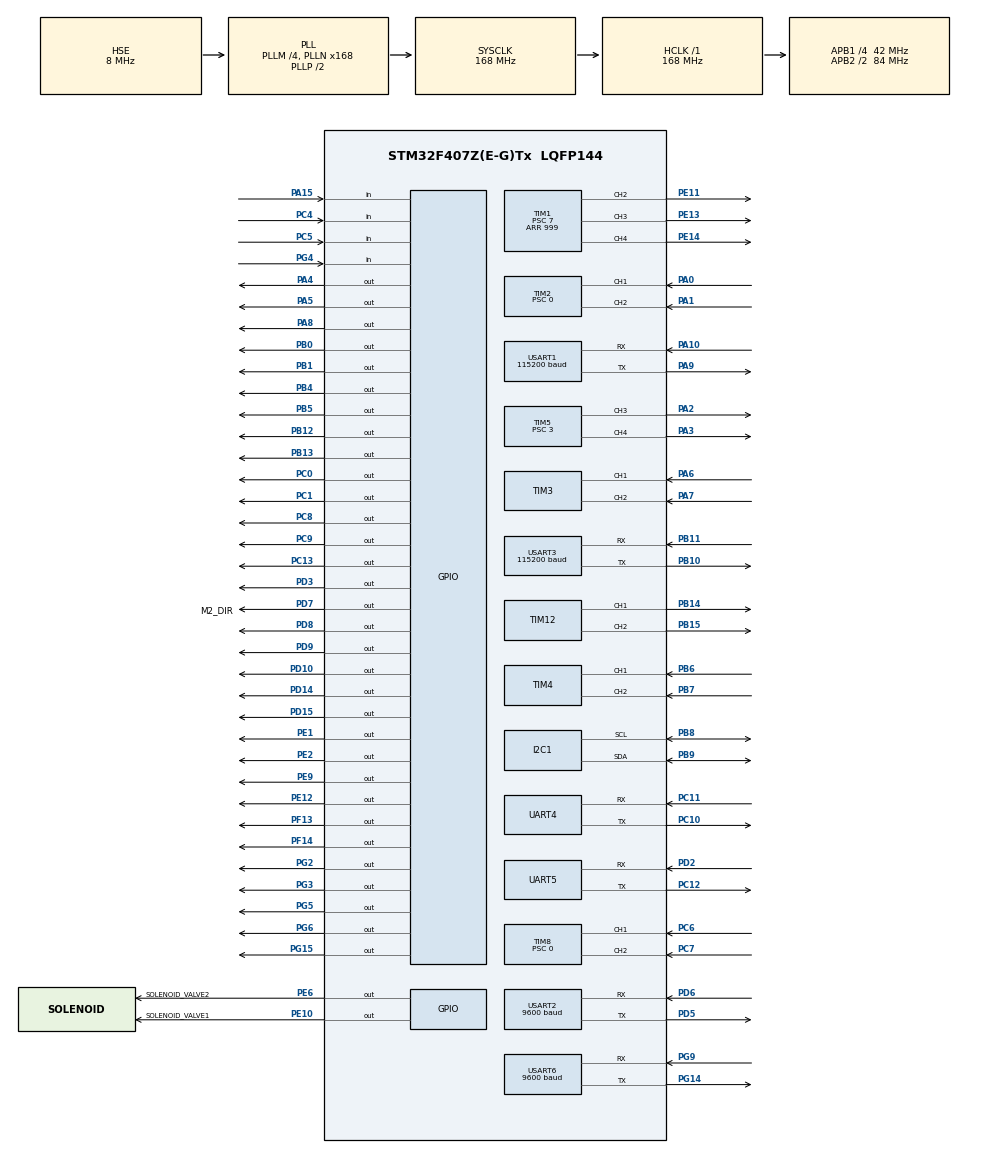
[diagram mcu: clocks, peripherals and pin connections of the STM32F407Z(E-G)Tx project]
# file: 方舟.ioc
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Dma.Request0=UART4_RX
Dma.Request1=UART4_TX
Dma.Request2=USART1_RX
Dma.Request3=USART1_TX
Dma.Request4=USART2_RX
Dma.Request5=USART2_TX
Dma.Request6=UART5_RX
Dma.Request7=UART5_TX
Dma.Request8=USART6_RX
Dma.Request9=USART6_TX
Dma.UART4_RX.0.Direction=DMA_PERIPH_TO_MEMORY
Dma.UART4_RX.0.FIFOMode=DMA_FIFOMODE_DISABLE
Dma.UART4_RX.0.Instance=DMA1_Stream2
Dma.UART4_RX.0.MemDataAlignment=DMA_MDATAALIGN_BYTE
Dma.UART4_RX.0.MemInc=DMA_MINC_ENABLE
Dma.UART4_RX.0.Mode=DMA_CIRCULAR
Dma.UART4_RX.0.PeriphDataAlignment=DMA_PDATAALIGN_BYTE
Dma.UART4_RX.0.PeriphInc=DMA_PINC_DISABLE
Dma.UART4_RX.0.Priority=DMA_PRIORITY_LOW
Dma.UART4_TX.1.Direction=DMA_MEMORY_TO_PERIPH
Dma.UART4_TX.1.FIFOMode=DMA_FIFOMODE_DISABLE
Dma.UART4_TX.1.Instance=DMA1_Stream4
Dma.UART4_TX.1.MemDataAlignment=DMA_MDATAALIGN_BYTE
Dma.UART4_TX.1.MemInc=DMA_MINC_ENABLE
Dma.UART4_TX.1.Mode=DMA_NORMAL
Dma.UART4_TX.1.PeriphDataAlignment=DMA_PDATAALIGN_BYTE
Dma.UART4_TX.1.PeriphInc=DMA_PINC_DISABLE
Dma.UART4_TX.1.Priority=DMA_PRIORITY_LOW
Dma.UART5_RX.6.Direction=DMA_PERIPH_TO_MEMORY
Dma.UART5_RX.6.FIFOMode=DMA_FIFOMODE_DISABLE
Dma.UART5_RX.6.Instance=DMA1_Stream0
Dma.UART5_RX.6.MemDataAlignment=DMA_MDATAALIGN_BYTE
Dma.UART5_RX.6.MemInc=DMA_MINC_ENABLE
Dma.UART5_RX.6.Mode=DMA_CIRCULAR
Dma.UART5_RX.6.PeriphDataAlignment=DMA_PDATAALIGN_BYTE
Dma.UART5_RX.6.PeriphInc=DMA_PINC_DISABLE
Dma.UART5_RX.6.Priority=DMA_PRIORITY_LOW
Dma.UART5_TX.7.Direction=DMA_MEMORY_TO_PERIPH
Dma.UART5_TX.7.FIFOMode=DMA_FIFOMODE_DISABLE
Dma.UART5_TX.7.Instance=DMA1_Stream7
Dma.UART5_TX.7.MemDataAlignment=DMA_MDATAALIGN_BYTE
Dma.UART5_TX.7.MemInc=DMA_MINC_ENABLE
Dma.UART5_TX.7.Mode=DMA_NORMAL
Dma.UART5_TX.7.PeriphDataAlignment=DMA_PDATAALIGN_BYTE
Dma.UART5_TX.7.PeriphInc=DMA_PINC_DISABLE
Dma.UART5_TX.7.Priority=DMA_PRIORITY_LOW
Dma.USART1_RX.2.Direction=DMA_PERIPH_TO_MEMORY
Dma.USART1_RX.2.FIFOMode=DMA_FIFOMODE_DISABLE
Dma.USART1_RX.2.Instance=DMA2_Stream2
Dma.USART1_RX.2.MemDataAlignment=DMA_MDATAALIGN_BYTE
Dma.USART1_RX.2.MemInc=DMA_MINC_ENABLE
Dma.USART1_RX.2.Mode=DMA_CIRCULAR
Dma.USART1_RX.2.PeriphDataAlignment=DMA_PDATAALIGN_BYTE
Dma.USART1_RX.2.PeriphInc=DMA_PINC_DISABLE
Dma.USART1_RX.2.Priority=DMA_PRIORITY_LOW
Dma.USART1_TX.3.Direction=DMA_MEMORY_TO_PERIPH
Dma.USART1_TX.3.FIFOMode=DMA_FIFOMODE_DISABLE
Dma.USART1_TX.3.Instance=DMA2_Stream7
Dma.USART1_TX.3.MemDataAlignment=DMA_MDATAALIGN_BYTE
Dma.USART1_TX.3.MemInc=DMA_MINC_ENABLE
Dma.USART1_TX.3.Mode=DMA_NORMAL
Dma.USART1_TX.3.PeriphDataAlignment=DMA_PDATAALIGN_BYTE
Dma.USART1_TX.3.PeriphInc=DMA_PINC_DISABLE
Dma.USART1_TX.3.Priority=DMA_PRIORITY_LOW
Dma.USART2_RX.4.Direction=DMA_PERIPH_TO_MEMORY
Dma.USART2_RX.4.FIFOMode=DMA_FIFOMODE_DISABLE
Dma.USART2_RX.4.Instance=DMA1_Stream5
Dma.USART2_RX.4.MemDataAlignment=DMA_MDATAALIGN_BYTE
Dma.USART2_RX.4.MemInc=DMA_MINC_ENABLE
Dma.USART2_RX.4.Mode=DMA_CIRCULAR
Dma.USART2_RX.4.PeriphDataAlignment=DMA_PDATAALIGN_BYTE
Dma.USART2_RX.4.PeriphInc=DMA_PINC_DISABLE
Dma.USART2_RX.4.Priority=DMA_PRIORITY_LOW
Dma.USART2_TX.5.Direction=DMA_MEMORY_TO_PERIPH
Dma.USART2_TX.5.FIFOMode=DMA_FIFOMODE_DISABLE
Dma.USART2_TX.5.Instance=DMA1_Stream6
Dma.USART2_TX.5.MemDataAlignment=DMA_MDATAALIGN_BYTE
Dma.USART2_TX.5.MemInc=DMA_MINC_ENABLE
Dma.USART2_TX.5.Mode=DMA_NORMAL
Dma.USART2_TX.5.PeriphDataAlignment=DMA_PDATAALIGN_BYTE
Dma.USART2_TX.5.PeriphInc=DMA_PINC_DISABLE
Dma.USART2_TX.5.Priority=DMA_PRIORITY_LOW
Dma.USART6_RX.8.Direction=DMA_PERIPH_TO_MEMORY
Dma.USART6_RX.8.FIFOMode=DMA_FIFOMODE_DISABLE
Dma.USART6_RX.8.Instance=DMA2_Stream1
Dma.USART6_RX.8.MemDataAlignment=DMA_MDATAALIGN_BYTE
Dma.USART6_RX.8.MemInc=DMA_MINC_ENABLE
Dma.USART6_RX.8.Mode=DMA_CIRCULAR
Dma.USART6_RX.8.PeriphDataAlignment=DMA_PDATAALIGN_BYTE
Dma.USART6_RX.8.PeriphInc=DMA_PINC_DISABLE
Dma.USART6_RX.8.Priority=DMA_PRIORITY_LOW
Dma.USART6_TX.9.Direction=DMA_MEMORY_TO_PERIPH
Dma.USART6_TX.9.FIFOMode=DMA_FIFOMODE_DISABLE
Dma.USART6_TX.9.Instance=DMA2_Stream6
Dma.USART6_TX.9.MemDataAlignment=DMA_MDATAALIGN_BYTE
Dma.USART6_TX.9.MemInc=DMA_MINC_ENABLE
Dma.USART6_TX.9.Mode=DMA_NORMAL
Dma.USART6_TX.9.PeriphDataAlignment=DMA_PDATAALIGN_BYTE
Dma.USART6_TX.9.PeriphInc=DMA_PINC_DISABLE
Dma.USART6_TX.9.Priority=DMA_PRIORITY_LOW
I2C1.I2C_Mode=I2C_Fast
Mcu.Family=STM32F4
Mcu.Name=STM32F407Z(E-G)Tx
Mcu.Package=LQFP144
NVIC.DMA1_Stream0_IRQn=true\:0\:0\:false\:false\:true\:false\:true\:true
NVIC.DMA1_Stream2_IRQn=true\:0\:0\:false\:false\:true\:false\:true\:true
NVIC.DMA1_Stream4_IRQn=true\:0\:0\:false\:false\:true\:false\:true\:true
NVIC.DMA1_Stream5_IRQn=true\:0\:0\:false\:false\:true\:false\:true\:true
NVIC.DMA1_Stream6_IRQn=true\:0\:0\:false\:false\:true\:false\:true\:true
NVIC.DMA1_Stream7_IRQn=true\:0\:0\:false\:false\:true\:false\:true\:true
NVIC.DMA2_Stream1_IRQn=true\:0\:0\:false\:false\:true\:false\:true\:true
NVIC.DMA2_Stream2_IRQn=true\:0\:0\:false\:false\:true\:false\:true\:true
NVIC.DMA2_Stream6_IRQn=true\:0\:0\:false\:false\:true\:false\:true\:true
NVIC.DMA2_Stream7_IRQn=true\:0\:0\:false\:false\:true\:false\:true\:true
NVIC.PriorityGroup=NVIC_PRIORITYGROUP_4
NVIC.TIM6_DAC_IRQn=true\:0\:0\:false\:false\:true\:true\:true\:true
NVIC.UART4_IRQn=true\:0\:0\:false\:false\:true\:true\:true\:true
NVIC.UART5_IRQn=true\:0\:0\:false\:false\:true\:true\:true\:true
NVIC.USART1_IRQn=true\:0\:0\:false\:false\:true\:true\:true\:true
NVIC.USART2_IRQn=true\:0\:0\:false\:false\:true\:true\:true\:true
NVIC.USART3_IRQn=true\:0\:0\:false\:false\:true\:true\:true\:true
NVIC.USART6_IRQn=true\:0\:0\:false\:false\:true\:true\:true\:true
PA0-WKUP.Signal=S_TIM2_CH1_ETR
PA1.Signal=S_TIM2_CH2
PA10.Mode=Asynchronous
PA10.Signal=USART1_RX
PA13.Mode=Serial_Wire
PA13.Signal=SYS_JTMS-SWDIO
PA14.Mode=Serial_Wire
PA14.Signal=SYS_JTCK-SWCLK
PA15.GPIO_PuPd=GPIO_PULLUP
PA15.Signal=GPIO_Input
PA2.Signal=S_TIM5_CH3
PA3.Signal=S_TIM5_CH4
PA4.Signal=GPIO_Output
PA5.Signal=GPIO_Output
PA6.Signal=S_TIM3_CH1
PA7.Signal=S_TIM3_CH2
PA8.Signal=GPIO_Output
PA9.Mode=Asynchronous
PA9.Signal=USART1_TX
PB0.Signal=GPIO_Output
PB1.Signal=GPIO_Output
PB10.Mode=Asynchronous
PB10.Signal=USART3_TX
PB11.Mode=Asynchronous
PB11.Signal=USART3_RX
PB12.Signal=GPIO_Output
PB13.Signal=GPIO_Output
PB14.Signal=S_TIM12_CH1
PB15.Signal=S_TIM12_CH2
PB4.Signal=GPIO_Output
PB5.Signal=GPIO_Output
PB6.Signal=S_TIM4_CH1
PB7.Signal=S_TIM4_CH2
PB8.Mode=I2C
PB8.Signal=I2C1_SCL
PB9.Mode=I2C
PB9.Signal=I2C1_SDA
PC0.GPIO_ModeDefaultOutputPP=GPIO_MODE_OUTPUT_PP
PC0.GPIO_PuPd=GPIO_PULLUP
PC0.GPIO_Speed=GPIO_SPEED_FREQ_HIGH
PC0.Signal=GPIO_Output
PC1.GPIO_ModeDefaultOutputPP=GPIO_MODE_OUTPUT_PP
PC1.GPIO_PuPd=GPIO_PULLUP
PC1.GPIO_Speed=GPIO_SPEED_FREQ_HIGH
PC1.Signal=GPIO_Output
PC10.Mode=Asynchronous
PC10.Signal=UART4_TX
PC11.Mode=Asynchronous
PC11.Signal=UART4_RX
PC12.Mode=Asynchronous
PC12.Signal=UART5_TX
PC13-ANTI_TAMP.Signal=GPIO_Output
PC14-OSC32_IN.Mode=LSE-External-Oscillator
PC14-OSC32_IN.Signal=RCC_OSC32_IN
PC15-OSC32_OUT.Mode=LSE-External-Oscillator
PC15-OSC32_OUT.Signal=RCC_OSC32_OUT
PC4.Signal=GPIO_Input
PC5.Signal=GPIO_Input
PC6.Signal=S_TIM8_CH1
PC7.Signal=S_TIM8_CH2
PC8.Signal=GPIO_Output
PC9.Signal=GPIO_Output
PD10.GPIO_Speed=GPIO_SPEED_FREQ_MEDIUM
PD10.PinState=GPIO_PIN_SET
PD10.Signal=GPIO_Output
PD14.Signal=GPIO_Output
PD15.Signal=GPIO_Output
PD2.Mode=Asynchronous
PD2.Signal=UART5_RX
PD3.GPIO_PuPd=GPIO_PULLUP
PD3.GPIO_Speed=GPIO_SPEED_FREQ_HIGH
PD3.PinState=GPIO_PIN_SET
PD3.Signal=GPIO_Output
PD5.Mode=Asynchronous
PD5.Signal=USART2_TX
PD6.Mode=Asynchronous
PD6.Signal=USART2_RX
PD7.GPIO_Label=M2_DIR
PD7.Signal=GPIO_Output
PD8.GPIO_Speed=GPIO_SPEED_FREQ_MEDIUM
PD8.PinState=GPIO_PIN_SET
PD8.Signal=GPIO_Output
PD9.GPIO_Speed=GPIO_SPEED_FREQ_MEDIUM
PD9.PinState=GPIO_PIN_SET
PD9.Signal=GPIO_Output
PE1.Signal=GPIO_Output
PE10.GPIO_Label=SOLENOID_VALVE1
PE10.GPIO_Speed=GPIO_SPEED_FREQ_HIGH
PE10.Signal=GPIO_Output
PE11.Signal=S_TIM1_CH2
PE12.GPIO_Speed=GPIO_SPEED_FREQ_HIGH
PE12.Signal=GPIO_Output
PE13.Signal=S_TIM1_CH3
PE14.Signal=S_TIM1_CH4
PE2.Signal=GPIO_Output
PE6.GPIO_Label=SOLENOID_VALVE2
PE6.GPIO_Speed=GPIO_SPEED_FREQ_HIGH
PE6.Signal=GPIO_Output
PE9.GPIO_Speed=GPIO_SPEED_FREQ_HIGH
PE9.Signal=GPIO_Output
PF13.GPIO_Speed=GPIO_SPEED_FREQ_HIGH
PF13.Signal=GPIO_Output
PF14.GPIO_Speed=GPIO_SPEED_FREQ_HIGH
PF14.Signal=GPIO_Output
PG14.Mode=Asynchronous
PG14.Signal=USART6_TX
PG15.Signal=GPIO_Output
PG2.Signal=GPIO_Output
PG3.Signal=GPIO_Output
PG4.GPIO_PuPd=GPIO_PULLUP
PG4.Signal=GPIO_Input
PG5.Signal=GPIO_Output
PG6.Signal=GPIO_Output
PG9.Mode=Asynchronous
PG9.Signal=USART6_RX
PH0-OSC_IN.Mode=HSE-External-Oscillator
PH0-OSC_IN.Signal=RCC_OSC_IN
PH1-OSC_OUT.Mode=HSE-External-Oscillator
PH1-OSC_OUT.Signal=RCC_OSC_OUT
ProjectManager.HeapSize=0x200
ProjectManager.StackSize=0x400
ProjectManager.TargetToolchain=MDK-ARM V5.32
RCC.48MHZClocksFreq_Value=84000000
RCC.AHBFreq_Value=168000000
RCC.APB1CLKDivider=RCC_HCLK_DIV4
RCC.APB1Freq_Value=42000000
RCC.APB1TimFreq_Value=84000000
RCC.APB2CLKDivider=RCC_HCLK_DIV2
RCC.APB2Freq_Value=84000000
RCC.APB2TimFreq_Value=168000000
RCC.CortexFreq_Value=168000000
RCC.HCLKFreq_Value=168000000
RCC.HSE_VALUE=8000000
RCC.HSI_VALUE=16000000
RCC.PLLM=4
RCC.PLLN=168
RCC.PLLSourceVirtual=RCC_PLLSOURCE_HSE
RCC.SYSCLKFreq_VALUE=168000000
RCC.SYSCLKSource=RCC_SYSCLKSOURCE_PLLCLK
RCC.VCOOutputFreq_Value=336000000
SH.S_TIM12_CH1.0=TIM12_CH1,PWM Generation1 CH1
SH.S_TIM12_CH2.0=TIM12_CH2,PWM Generation2 CH2
SH.S_TIM1_CH2.0=TIM1_CH2,PWM Generation2 CH2
SH.S_TIM1_CH3.0=TIM1_CH3,PWM Generation3 CH3
SH.S_TIM1_CH4.0=TIM1_CH4,PWM Generation4 CH4
SH.S_TIM2_CH1_ETR.0=TIM2_CH1,Encoder_Interface
SH.S_TIM2_CH2.0=TIM2_CH2,Encoder_Interface
SH.S_TIM3_CH1.0=TIM3_CH1,Encoder_Interface
SH.S_TIM3_CH2.0=TIM3_CH2,Encoder_Interface
SH.S_TIM4_CH1.0=TIM4_CH1,Encoder_Interface
SH.S_TIM4_CH2.0=TIM4_CH2,Encoder_Interface
SH.S_TIM5_CH3.0=TIM5_CH3,PWM Generation3 CH3
SH.S_TIM5_CH4.0=TIM5_CH4,PWM Generation4 CH4
SH.S_TIM8_CH1.0=TIM8_CH1,Encoder_Interface
SH.S_TIM8_CH2.0=TIM8_CH2,Encoder_Interface
TIM1.AutoReloadPreload=TIM_AUTORELOAD_PRELOAD_ENABLE
TIM1.Channel-PWM\ Generation2\ CH2=TIM_CHANNEL_2
TIM1.Channel-PWM\ Generation3\ CH3=TIM_CHANNEL_3
TIM1.Channel-PWM\ Generation4\ CH4=TIM_CHANNEL_4
TIM1.Period=999
TIM1.Prescaler=7
TIM12.Channel-PWM\ Generation1\ CH1=TIM_CHANNEL_1
TIM12.Channel-PWM\ Generation2\ CH2=TIM_CHANNEL_2
TIM2.AutoReloadPreload=TIM_AUTORELOAD_PRELOAD_ENABLE
TIM2.EncoderMode=TIM_ENCODERMODE_TI12
TIM2.Period=4294967295
TIM2.Prescaler=0
TIM3.EncoderMode=TIM_ENCODERMODE_TI12
TIM4.EncoderMode=TIM_ENCODERMODE_TI12
TIM5.AutoReloadPreload=TIM_AUTORELOAD_PRELOAD_ENABLE
TIM5.Channel-PWM\ Generation3\ CH3=TIM_CHANNEL_3
TIM5.Channel-PWM\ Generation4\ CH4=TIM_CHANNEL_4
TIM5.Period=999
TIM5.Prescaler=3
TIM5.Pulse-PWM\ Generation3\ CH3=500
TIM6.AutoReloadPreload=TIM_AUTORELOAD_PRELOAD_ENABLE
TIM6.Period=999
TIM6.Prescaler=83
TIM8.AutoReloadPreload=TIM_AUTORELOAD_PRELOAD_ENABLE
TIM8.EncoderMode=TIM_ENCODERMODE_TI12
TIM8.Period=65535
TIM8.Prescaler=0
UART4.VirtualMode=Asynchronous
UART5.VirtualMode=Asynchronous
USART1.BaudRate=115200
USART1.VirtualMode=VM_ASYNC
USART2.BaudRate=9600
USART2.VirtualMode=VM_ASYNC
USART3.BaudRate=115200
USART3.VirtualMode=VM_ASYNC
USART6.BaudRate=9600
USART6.VirtualMode=VM_ASYNC
VP_TIM12_VS_ClockSourceINT.Mode=Internal
VP_TIM1_VS_ClockSourceINT.Mode=Internal
VP_TIM5_VS_ClockSourceINT.Mode=Internal
VP_TIM6_VS_ClockSourceINT.Mode=Enable_Timer
board=custom

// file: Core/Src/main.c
/* USER CODE BEGIN Header */
/**
  ******************************************************************************
  * @file           : main.c
  * @brief          : Main program body
  ******************************************************************************
  */
/* USER CODE END Header */
#include "main.h"
#include "dma.h"
#include "i2c.h"
#include "tim.h"
#include "usart.h"
#include "gpio.h"

/* USER CODE BEGIN Includes */
#include "app_control.h"
#include "bluetooth.h"
#include "serial_protocol.h"

#include "motor_driver_X42S.h"
#include "oled.h"
#include "soft_i2c.h"
#include "solenoid_valve.h"
/* USER CODE END Includes */

void SystemClock_Config(void);

int main(void)
{

  /* MCU Configuration--------------------------------------------------------*/

  /* Reset of all peripherals, Initializes the Flash interface and the Systick. */
  HAL_Init();

  /* Configure the system clock */
  SystemClock_Config();

  /* Initialize all configured peripherals */
  MX_GPIO_Init();
  MX_DMA_Init();
  MX_TIM2_Init();
  MX_USART1_UART_Init();
  MX_USART3_UART_Init();
  MX_I2C1_Init();
  MX_TIM1_Init();
  MX_TIM5_Init();
  MX_UART4_Init();
  MX_UART5_Init();
  MX_USART2_UART_Init();
  MX_TIM6_Init();
  MX_TIM8_Init();
  MX_USART6_UART_Init();
  MX_TIM3_Init();
  MX_TIM4_Init();
  MX_TIM12_Init();
  /* USER CODE BEGIN 2 */

  /* Stop any X42S driver-stored boot motion before other subsystems. */
  MotorDriverX42S_Serial_Init();

  Soft_I2C_Init();
  OLED_Init();
  OLED_Clear();

  /* ---- 步进电机串口测试（上电跑一次，量产�?#if 0�?--- */
#if 0
//uint8_t cmd []={0x01, 0xF6, 0x00, 0x00, 0x64, 0x00, 0x00, 0x6B };
//HAL_UART_Transmit(&huart6,cmd,sizeof(cmd),HAL_MAX_DELAY);
//MotorDriverX42S_SetLiftSpeed(100);  /* 正转 100 RPM */
//while(1);
  MotorDriverX42S_Serial_Test();
#endif

  /* 初始化麦轮控制（包含电机驱动和闭环控制） */
  Mecanum_Init();
  SolenoidValve_Init();

  /* 初始化蓝�?*/
  Bluetooth_Init();
  Bluetooth_StartReceiveIT();

  SerialProtocol_Init();
  SerialProtocol_StartReceiveIT();

  OLED_Clear();
  OLED_ShowString(0, 0, "READY", 16, 0);
  SerialProtocol_ShowStatus();
  /* USER CODE END 2 */

  /* Infinite loop */
  /* USER CODE BEGIN WHILE */

  /* 确保上电后急停LED初始熄灭 */
  HAL_GPIO_WritePin(GPIOD, GPIO_PIN_9, GPIO_PIN_SET);   /* PD9 emergency-stop LED off (active low) */

  while (1)
  {
    /* USER CODE END WHILE */

    /* USER CODE BEGIN 3 */

    /* 蓝牙控制任务（麦�?绘图�?*/
    /* PG4 急停按键检�?*/
    App_EmergencyStopCheck();
    App_ControlTask();
    MotorDriverX42S_ControlTask();
    SolenoidValve_Task();
    /* 自动绘图任务 */
    App_AutoPlotTask();

    SerialProtocol_Task();
    HAL_Delay(10);

    /* PD9 运行指示灯：�?500ms 翻转一�?*/
  }
  /* USER CODE END 3 */
}

void SystemClock_Config(void)
{
  RCC_OscInitTypeDef RCC_OscInitStruct = {0};
  RCC_ClkInitTypeDef RCC_ClkInitStruct = {0};

  /** Configure the main internal regulator output voltage
  */
  __HAL_RCC_PWR_CLK_ENABLE();
  __HAL_PWR_VOLTAGESCALING_CONFIG(PWR_REGULATOR_VOLTAGE_SCALE1);

  /** Initializes the RCC Oscillators according to the specified parameters
  * in the RCC_OscInitTypeDef structure.
  */
  RCC_OscInitStruct.OscillatorType = RCC_OSCILLATORTYPE_HSE;
  RCC_OscInitStruct.HSEState = RCC_HSE_ON;
  RCC_OscInitStruct.PLL.PLLState = RCC_PLL_ON;
  RCC_OscInitStruct.PLL.PLLSource = RCC_PLLSOURCE_HSE;
  RCC_OscInitStruct.PLL.PLLM = 4;
  RCC_OscInitStruct.PLL.PLLN = 168;
  RCC_OscInitStruct.PLL.PLLP = RCC_PLLP_DIV2;
  RCC_OscInitStruct.PLL.PLLQ = 4;
  if (HAL_RCC_OscConfig(&RCC_OscInitStruct) != HAL_OK)
  {
    Error_Handler();
  }

  /** Initializes the CPU, AHB and APB buses clocks
  */
  RCC_ClkInitStruct.ClockType = RCC_CLOCKTYPE_HCLK|RCC_CLOCKTYPE_SYSCLK
                              |RCC_CLOCKTYPE_PCLK1|RCC_CLOCKTYPE_PCLK2;
  RCC_ClkInitStruct.SYSCLKSource = RCC_SYSCLKSOURCE_PLLCLK;
  RCC_ClkInitStruct.AHBCLKDivider = RCC_SYSCLK_DIV1;
  RCC_ClkInitStruct.APB1CLKDivider = RCC_HCLK_DIV4;
  RCC_ClkInitStruct.APB2CLKDivider = RCC_HCLK_DIV2;

  if (HAL_RCC_ClockConfig(&RCC_ClkInitStruct, FLASH_LATENCY_5) != HAL_OK)
  {
    Error_Handler();
  }
}

void Error_Handler(void)
{
  __disable_irq();
  while (1)
  {
  }
}
